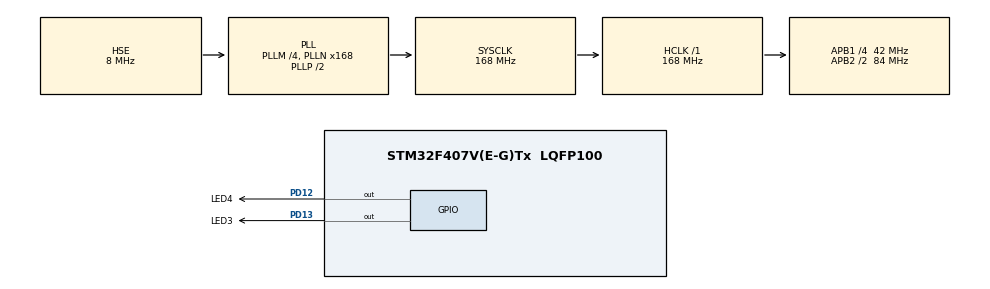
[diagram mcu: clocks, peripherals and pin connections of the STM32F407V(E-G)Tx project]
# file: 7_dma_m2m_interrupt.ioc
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Dma.MEMTOMEM.0.Direction=DMA_MEMORY_TO_MEMORY
Dma.MEMTOMEM.0.FIFOMode=DMA_FIFOMODE_ENABLE
Dma.MEMTOMEM.0.FIFOThreshold=DMA_FIFO_THRESHOLD_FULL
Dma.MEMTOMEM.0.Instance=DMA2_Stream0
Dma.MEMTOMEM.0.MemBurst=DMA_MBURST_SINGLE
Dma.MEMTOMEM.0.MemDataAlignment=DMA_MDATAALIGN_BYTE
Dma.MEMTOMEM.0.MemInc=DMA_MINC_ENABLE
Dma.MEMTOMEM.0.Mode=DMA_NORMAL
Dma.MEMTOMEM.0.PeriphBurst=DMA_PBURST_SINGLE
Dma.MEMTOMEM.0.PeriphDataAlignment=DMA_PDATAALIGN_BYTE
Dma.MEMTOMEM.0.PeriphInc=DMA_PINC_ENABLE
Dma.MEMTOMEM.0.Priority=DMA_PRIORITY_LOW
Dma.Request0=MEMTOMEM
Mcu.Family=STM32F4
Mcu.Name=STM32F407V(E-G)Tx
Mcu.Package=LQFP100
NVIC.DMA2_Stream0_IRQn=true\:1\:0\:true\:false\:true\:true\:true
NVIC.PriorityGroup=NVIC_PRIORITYGROUP_4
PA13.Mode=Serial_Wire
PA13.Signal=SYS_JTMS-SWDIO
PA14.Mode=Serial_Wire
PA14.Signal=SYS_JTCK-SWCLK
PD12.GPIO_Label=LED4
PD12.Signal=GPIO_Output
PD13.GPIO_Label=LED3
PD13.Signal=GPIO_Output
PH0-OSC_IN.Mode=HSE-External-Oscillator
PH0-OSC_IN.Signal=RCC_OSC_IN
PH1-OSC_OUT.Mode=HSE-External-Oscillator
PH1-OSC_OUT.Signal=RCC_OSC_OUT
ProjectManager.HeapSize=0x2000
ProjectManager.StackSize=0x4000
ProjectManager.TargetToolchain=MDK-ARM V5.27
RCC.48MHZClocksFreq_Value=84000000
RCC.AHBFreq_Value=168000000
RCC.APB1CLKDivider=RCC_HCLK_DIV4
RCC.APB1Freq_Value=42000000
RCC.APB1TimFreq_Value=84000000
RCC.APB2CLKDivider=RCC_HCLK_DIV2
RCC.APB2Freq_Value=84000000
RCC.APB2TimFreq_Value=168000000
RCC.CortexFreq_Value=168000000
RCC.HCLKFreq_Value=168000000
RCC.HSE_VALUE=8000000
RCC.HSI_VALUE=16000000
RCC.LSE_VALUE=32768
RCC.PLLM=4
RCC.PLLN=168
RCC.PLLSourceVirtual=RCC_PLLSOURCE_HSE
RCC.SYSCLKFreq_VALUE=168000000
RCC.SYSCLKSource=RCC_SYSCLKSOURCE_PLLCLK
RCC.VCOOutputFreq_Value=336000000
board=custom

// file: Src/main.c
/* USER CODE BEGIN Header */
/**
  ******************************************************************************
  * @file           : main.c
  * @brief          : Main program body
  ******************************************************************************
  * @attention
  *
  * <h2><center>&copy; Copyright (c) 2020 STMicroelectronics.
  * All rights reserved.</center></h2>
  *
  * This software component is licensed by ST under BSD 3-Clause license,
  * the "License"; You may not use this file except in compliance with the
  * License. You may obtain a copy of the License at:
  *                        opensource.org/licenses/BSD-3-Clause
  *
  ******************************************************************************
  */
/* USER CODE END Header */

#include "main.h"
#include "dma.h"
#include "gpio.h"

/* USER CODE BEGIN Includes */
#include <string.h>
/* USER CODE END Includes */

/* USER CODE BEGIN PD */
#define BUFFER_SIZE	10
/* USER CODE END PD */

void SystemClock_Config(void);
/* USER CODE BEGIN PFP */
void XferCpltCallback (DMA_HandleTypeDef *hdma); 	//user function if DMA transfer OK
void XferErrorCallback (DMA_HandleTypeDef *hdma); //user function if DMA transfer BAD
/* USER CODE END PFP */

/* USER CODE BEGIN 0 */
uint8_t buffer_src[BUFFER_SIZE] = {0, 1, 2, 3, 4, 5, 6, 7, 8, 9};
uint8_t buffer_dst[BUFFER_SIZE];
/* USER CODE END 0 */

int main(void)
{

  /* MCU Configuration--------------------------------------------------------*/

  /* Reset of all peripherals, Initializes the Flash interface and the Systick. */
  HAL_Init();

  /* Configure the system clock */
  SystemClock_Config();

  /* Initialize all configured peripherals */
  MX_GPIO_Init();
  MX_DMA_Init();
  /* USER CODE BEGIN 2 */
	hdma_memtomem_dma2_stream0.XferCpltCallback 	= &XferCpltCallback;
	hdma_memtomem_dma2_stream0.XferErrorCallback 	= &XferErrorCallback;
	HAL_DMA_Start_IT(&hdma_memtomem_dma2_stream0, (uint32_t)buffer_src, (uint32_t)buffer_dst, (sizeof(buffer_src) / sizeof(buffer_src)));
	if(!strcmp((char *)buffer_src, (char *)buffer_dst))
		HAL_GPIO_WritePin(LED3_GPIO_Port, LED3_Pin, GPIO_PIN_SET);
  /* USER CODE END 2 */

  /* Infinite loop */
  while (1)
  {

  }
}

void SystemClock_Config(void)
{
  RCC_OscInitTypeDef RCC_OscInitStruct = {0};
  RCC_ClkInitTypeDef RCC_ClkInitStruct = {0};

  /** Configure the main internal regulator output voltage
  */
  __HAL_RCC_PWR_CLK_ENABLE();
  __HAL_PWR_VOLTAGESCALING_CONFIG(PWR_REGULATOR_VOLTAGE_SCALE1);
  /** Initializes the CPU, AHB and APB busses clocks
  */
  RCC_OscInitStruct.OscillatorType = RCC_OSCILLATORTYPE_HSE;
  RCC_OscInitStruct.HSEState = RCC_HSE_ON;
  RCC_OscInitStruct.PLL.PLLState = RCC_PLL_ON;
  RCC_OscInitStruct.PLL.PLLSource = RCC_PLLSOURCE_HSE;
  RCC_OscInitStruct.PLL.PLLM = 4;
  RCC_OscInitStruct.PLL.PLLN = 168;
  RCC_OscInitStruct.PLL.PLLP = RCC_PLLP_DIV2;
  RCC_OscInitStruct.PLL.PLLQ = 4;
  if (HAL_RCC_OscConfig(&RCC_OscInitStruct) != HAL_OK)
  {
    Error_Handler();
  }
  /** Initializes the CPU, AHB and APB busses clocks
  */
  RCC_ClkInitStruct.ClockType = RCC_CLOCKTYPE_HCLK|RCC_CLOCKTYPE_SYSCLK
                              |RCC_CLOCKTYPE_PCLK1|RCC_CLOCKTYPE_PCLK2;
  RCC_ClkInitStruct.SYSCLKSource = RCC_SYSCLKSOURCE_PLLCLK;
  RCC_ClkInitStruct.AHBCLKDivider = RCC_SYSCLK_DIV1;
  RCC_ClkInitStruct.APB1CLKDivider = RCC_HCLK_DIV4;
  RCC_ClkInitStruct.APB2CLKDivider = RCC_HCLK_DIV2;

  if (HAL_RCC_ClockConfig(&RCC_ClkInitStruct, FLASH_LATENCY_5) != HAL_OK)
  {
    Error_Handler();
  }
}

/* USER CODE BEGIN 4 */
void XferCpltCallback (DMA_HandleTypeDef *hdma)
{
	HAL_GPIO_WritePin(LED4_GPIO_Port, LED4_Pin, GPIO_PIN_SET);
	HAL_Delay(50);
	HAL_GPIO_WritePin(LED4_GPIO_Port, LED4_Pin, GPIO_PIN_RESET);
}

void XferErrorCallback (DMA_HandleTypeDef *hdma)
{
	HAL_GPIO_WritePin(LED4_GPIO_Port, LED4_Pin, GPIO_PIN_SET);
	HAL_Delay(1000);
	HAL_GPIO_WritePin(LED4_GPIO_Port, LED4_Pin, GPIO_PIN_RESET);
}
/* USER CODE END 4 */

void Error_Handler(void)
{
}

/************************ (C) COPYRIGHT STMicroelectronics *****END OF FILE****/
